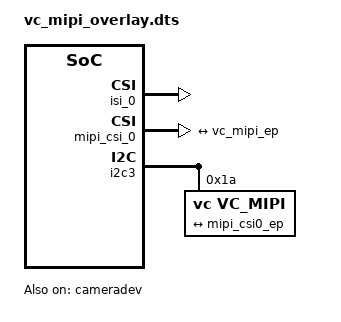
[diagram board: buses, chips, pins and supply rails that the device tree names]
/dts-v1/;
/plugin/;

&cameradev {
	status = "okay";
};

&isi_0 {
	status = "okay";

        cap_device {
		status = "okay";
	};
}

&mipi_csi_0 {
	#address-cells = <1>;
	#size-cells = <0>;
	status = "okay";
	port@0 {
		reg = <0>;
		mipi_csi0_ep: endpoint {
			remote-endpoint = <&vc_mipi_ep>;
			data-lanes = <2>; // Set <4> for 4 lanes
			csis-hs-settle = <22>;
			csis-clk-settle = <0>;
			csis-wclk;
		};
	};
};

&i2c3 { // Check on which
        #address-cells = <1>;
        #size-cells = <0>;
        status = "okay";

        vc_mipi@1a {
                compatible 	= "vc,vc_mipi";
                reg 		= <0x1a>;
                status 		= "okay";

                port {
                        vc_mipi_ep: endpoint {
                                clocks-lanes = <0>;
                                data-lanes = <1 2>; // Set <1 2 3 4> for 4 lanes
                                remote-endpoint = <&mipi_csi0_ep>;
                        };
                };
            };
};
